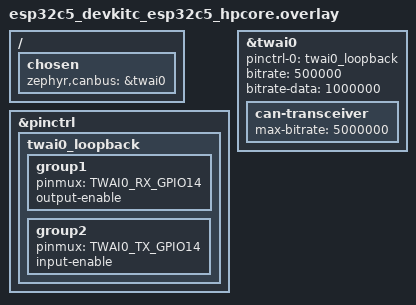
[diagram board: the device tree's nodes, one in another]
/*
 * Copyright (c) 2026 Espressif Systems (Shanghai) Co., Ltd.
 *
 * SPDX-License-Identifier: Apache-2.0
 */

#include <zephyr/dt-bindings/pinctrl/esp-pinctrl-common.h>
#include <zephyr/dt-bindings/pinctrl/esp32c5-pinctrl.h>
#include <zephyr/dt-bindings/pinctrl/esp32c5-gpio-sigmap.h>

/ {
	chosen {
		zephyr,canbus = &twai0;
	};
};

&pinctrl {
	/*
	 * Override the board default: route TWAI0 TX and RX to the same
	 * GPIO14 so internal loopback mode can exercise the full protocol
	 * engine without an external transceiver. output-enable on the RX
	 * pinmux and input-enable on the TX pinmux keep the pin
	 * bidirectional after both apply_state() passes.
	 */
	twai0_loopback: twai0_loopback {
		group1 {
			pinmux = <TWAI0_RX_GPIO14>;
			output-enable;
		};

		group2 {
			pinmux = <TWAI0_TX_GPIO14>;
			input-enable;
		};
	};
};

&twai0 {
	status = "okay";
	pinctrl-0 = <&twai0_loopback>;
	pinctrl-names = "default";
	bitrate = <500000>;
	bitrate-data = <1000000>;

	can-transceiver {
		max-bitrate = <5000000>;
	};
};
